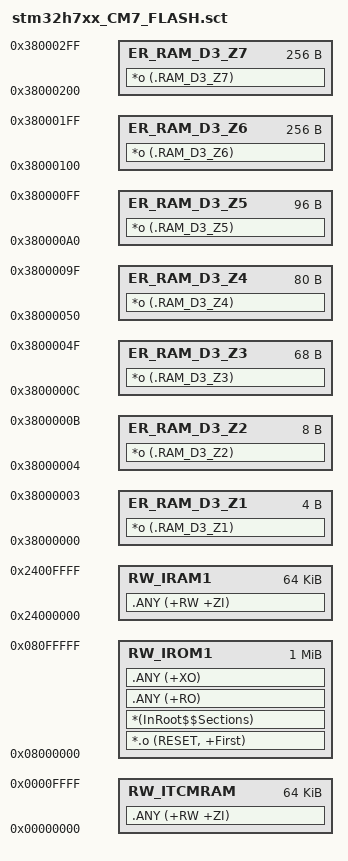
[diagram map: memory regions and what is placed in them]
; *************************************************************
; *** Scatter-Loading Description File generated by uVision ***
; *************************************************************

LR_IROM1 0x08000000 0x00100000  {    ; load region size_region
  RW_IROM1 0x08000000 0x00100000  {  ; load address = execution address
   *.o (RESET, +First)
   *(InRoot$$Sections)
   .ANY (+RO)
   .ANY (+XO)
  }
  RW_IRAM1 0x24000000 0x00010000  {  ; RW data
   .ANY (+RW +ZI)
  }

  RW_ITCMRAM 0x00000000 0x00010000  {
    .ANY (+RW +ZI)
  }

  ER_RAM_D3_Z1 0x38000000 0x00000004 {
    *o (.RAM_D3_Z1)
  }

  ER_RAM_D3_Z2 0x38000004 0x00000008 {
    *o (.RAM_D3_Z2)
  }

  ER_RAM_D3_Z3 0x3800000c ALIGN 4 0x00000044 {
    *o (.RAM_D3_Z3)
  }
  ER_RAM_D3_Z4 0x38000050 0x00000050 {
    *o (.RAM_D3_Z4)
  }

  ER_RAM_D3_Z5 0x380000A0 0x00000060 {
    *o (.RAM_D3_Z5)
  }

  ER_RAM_D3_Z6 0x38000100 0x00000100 {
    *o (.RAM_D3_Z6)
  }

  ER_RAM_D3_Z7 0x38000200 0x00000100 {
    *o (.RAM_D3_Z7)
  }



}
